# STM32F303 register map
File version: 1.7
Registers are 32-bit, read-write, reset 0x0 unless marked. A register's access mark holds for its fields unless they carry their own. Offsets are from the block's base; [hi:lo] are bit positions; {n}, {i} and the like mark numbered series.

## EXTI — External interrupt/event controller
Base 0x40010400
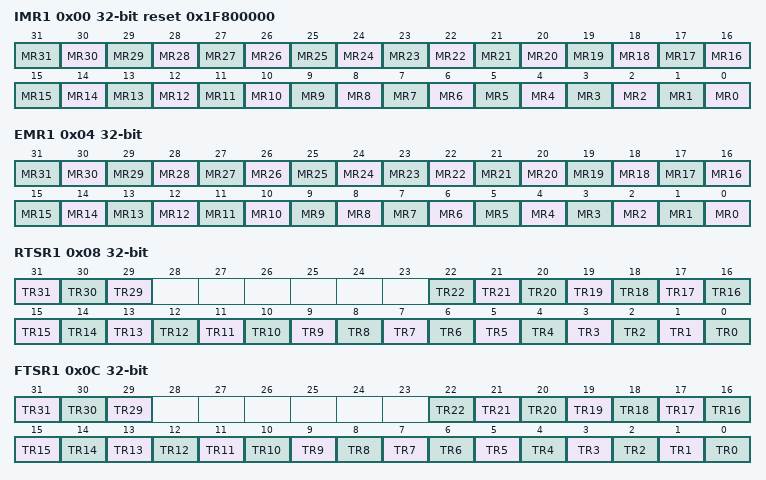
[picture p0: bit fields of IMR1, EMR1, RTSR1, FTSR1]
0x00 IMR1 reset 0x1F800000 — Interrupt mask register
  [n] MR{n} (n=0..31) — Interrupt Mask on line {n}
0x04 EMR1 — Event mask register
  [n] MR{n} (n=0..31) — Event Mask on line {n}
0x08 RTSR1 — Rising Trigger selection register
  [31] TR31 — Rising trigger event configuration of line 31
  [30] TR30 — Rising trigger event configuration of line 30
  [29] TR29 — Rising trigger event configuration of line 29
  [n] TR{n} (n=0..22) — Rising trigger event configuration of line {n}
0x0C FTSR1 — Falling Trigger selection register
  [31] TR31 — Falling trigger event configuration of line 31
  [30] TR30 — Falling trigger event configuration of line 30.
  [29] TR29 — Falling trigger event configuration of line 29
  [n] TR{n} (n=0..22) — Falling trigger event configuration of line {n}
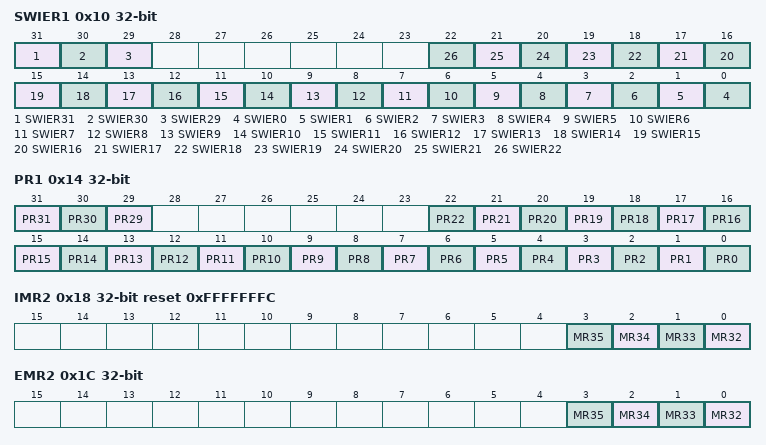
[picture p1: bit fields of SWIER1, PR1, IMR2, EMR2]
0x10 SWIER1 — Software interrupt event register
  [31] SWIER31 — Software Interrupt on line 319
  [30] SWIER30 — Software Interrupt on line 309
  [29] SWIER29 — Software Interrupt on line 29
  [n] SWIER{n} (n=0..22) — Software Interrupt on line {n}
0x14 PR1 — Pending register
  [31] PR31 — Pending bit 31
  [30] PR30 — Pending bit 30
  [29] PR29 — Pending bit 29
  [n] PR{n} (n=0..22) — Pending bit {n}
0x18 IMR2 reset 0xFFFFFFFC — Interrupt mask register
  [n-32] MR{n} (n=32..35) — Interrupt Mask on external/internal line {n}
0x1C EMR2 — Event mask register
  [n-32] MR{n} (n=32..35) — Event mask on external/internal line {n}
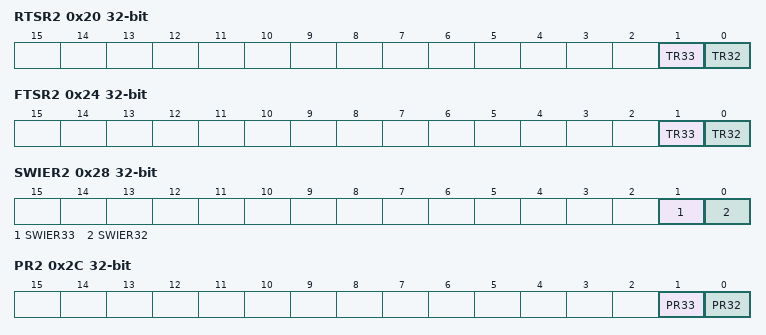
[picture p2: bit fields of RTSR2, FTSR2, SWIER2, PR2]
0x20 RTSR2 — Rising Trigger selection register
  [1] TR33 — Rising trigger event configuration bit of line 33
  [0] TR32 — Rising trigger event configuration bit of line 32
0x24 FTSR2 — Falling Trigger selection register
  [1] TR33 — Falling trigger event configuration bit of line 33
  [0] TR32 — Falling trigger event configuration bit of line 32
0x28 SWIER2 — Software interrupt event register
  [1] SWIER33 — Software interrupt on line 33
  [0] SWIER32 — Software interrupt on line 32
0x2C PR2 — Pending register
  [1] PR33 — Pending bit on line 33
  [0] PR32 — Pending bit on line 32

## PWR — Power control
Base 0x40007000
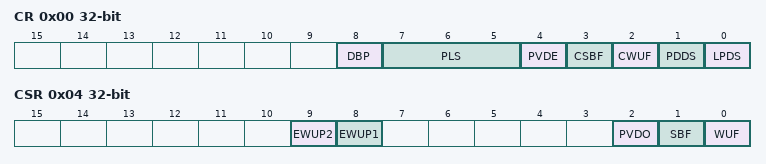
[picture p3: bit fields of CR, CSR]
0x00 CR — power control register
  [8] DBP — Disable backup domain write protection
  [7:5] PLS — PVD level selection
  [4] PVDE — Power voltage detector enable
  [3] CSBF — Clear standby flag
  [2] CWUF — Clear wakeup flag
  [1] PDDS — Power down deepsleep
  [0] LPDS — Low-power deep sleep
0x04 CSR access per field — power control/status register
  [9] EWUP2 rw — Enable WKUP2 pin
  [8] EWUP1 rw — Enable WKUP1 pin
  [2] PVDO ro — PVD output
  [1] SBF ro — Standby flag
  [0] WUF ro — Wakeup flag

## IWDG — Independent watchdog
Base 0x40003000
0x00 KR wo — Key register
  [15:0] KEY — Key value
0x04 PR — Prescaler register
  [2:0] PR — Prescaler divider
0x08 RLR reset 0xFFF — Reload register
  [11:0] RL — Watchdog counter reload value
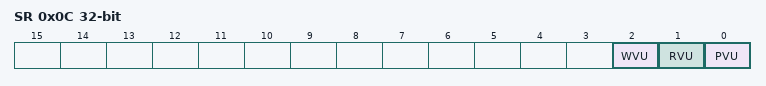
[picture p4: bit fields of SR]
0x0C SR ro — Status register
  [2] WVU — Watchdog counter window value update
  [1] RVU — Watchdog counter reload value update
  [0] PVU — Watchdog prescaler value update
0x10 WINR reset 0xFFF — Window register
  [11:0] WIN — Watchdog counter window value

## WWDG — Window watchdog
Base 0x40002C00
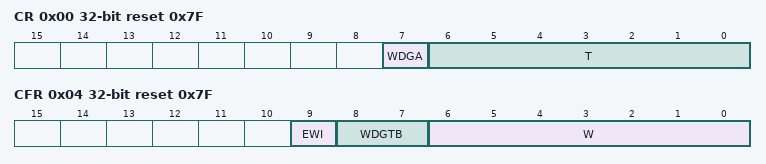
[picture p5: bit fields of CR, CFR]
0x00 CR reset 0x7F — Control register
  [7] WDGA — Activation bit
  [6:0] T — 7-bit counter
0x04 CFR reset 0x7F — Configuration register
  [9] EWI — Early wakeup interrupt
  [8:7] WDGTB — Timer base
  [6:0] W — 7-bit window value
0x08 SR — Status register
  [0] EWIF — Early wakeup interrupt flag

## DBGMCU — Debug support
Base 0xE0042000
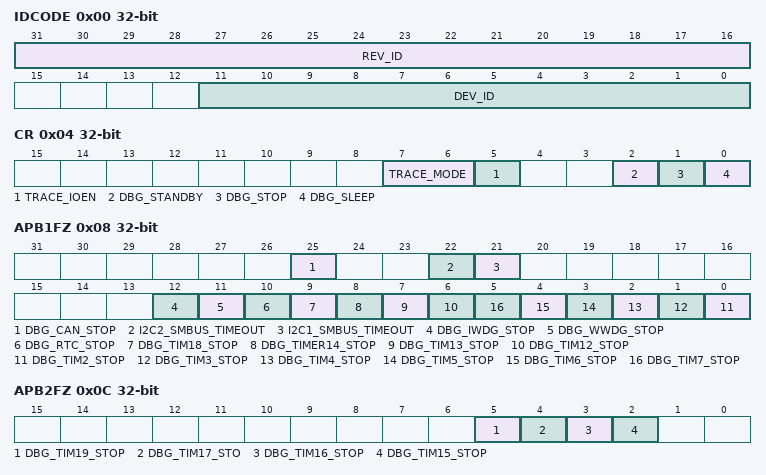
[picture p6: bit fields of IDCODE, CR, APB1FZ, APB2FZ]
0x00 IDCODE ro — MCU Device ID Code Register
  [31:16] REV_ID — Revision Identifier
  [11:0] DEV_ID — Device Identifier
0x04 CR — Debug MCU Configuration Register
  [7:6] TRACE_MODE — Trace pin assignment control
  [5] TRACE_IOEN — Trace pin assignment control
  [2] DBG_STANDBY — Debug Standby Mode
  [1] DBG_STOP — Debug Stop Mode
  [0] DBG_SLEEP — Debug Sleep mode
0x08 APB1FZ — APB Low Freeze Register
  [25] DBG_CAN_STOP — Debug CAN stopped when core is halted
  [22] I2C2_SMBUS_TIMEOUT — SMBUS timeout mode stopped when Core is halted
  [21] I2C1_SMBUS_TIMEOUT — SMBUS timeout mode stopped when Core is halted
  [12] DBG_IWDG_STOP — Debug Independent Wachdog stopped when Core is halted
  [11] DBG_WWDG_STOP — Debug Window Wachdog stopped when Core is halted
  [10] DBG_RTC_STOP — Debug RTC stopped when Core is halted
  [9] DBG_TIM18_STOP — Debug Timer 18 stopped when Core is halted
  [8] DBG_TIMER14_STOP — Debug Timer 14 stopped when Core is halted
  [7] DBG_TIM13_STOP — Debug Timer 13 stopped when Core is halted
  [6] DBG_TIM12_STOP — Debug Timer 12 stopped when Core is halted
  [n-2] DBG_TIM{n}_STOP (n=2..7) — Debug Timer {n} stopped when Core is halted
0x0C APB2FZ — APB High Freeze Register
  [5] DBG_TIM19_STOP — Debug Timer 19 stopped when Core is halted
  [4] DBG_TIM17_STO — Debug Timer 17 stopped when Core is halted
  [3] DBG_TIM16_STOP — Debug Timer 16 stopped when Core is halted
  [2] DBG_TIM15_STOP — Debug Timer 15 stopped when Core is halted
